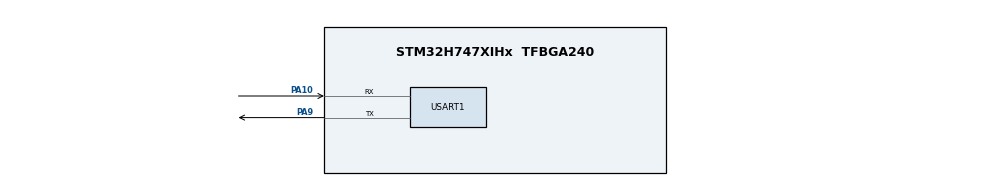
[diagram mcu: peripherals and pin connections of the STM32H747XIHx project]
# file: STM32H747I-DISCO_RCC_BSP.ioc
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Mcu.Family=STM32H7
RCC.CortexFreq_Value=400000000
RCC.HPRE=RCC_HCLK_DIV2
PH0-OSC_IN\ (PH0).PinAttribute=CortexM7
PH0-OSC_IN\ (PH0).Signal=RCC_OSC_IN
PC15-OSC32_OUT\ (OSC32_OUT).Mode=LSE-External-Oscillator
RCC.SYSCLKSource=RCC_SYSCLKSOURCE_PLLCLK
ProjectManager.StackSize=0x400
PA10.PinAttribute=CortexM7
RCC.HCLKFreq_Value=200000000
PH1-OSC_OUT\ (PH1).Mode=HSE-External-Oscillator
RCC.DIVM1=5
NVIC2.PriorityGroup=NVIC_PRIORITYGROUP_4
VP_SYS_M4_VS_Systick.Mode=SysTick
CortexM7.IPs=BDMA\:I,DMA\:I,FATFS_M7\:I,FREERTOS_M7\:I,IWDG1\:I,MDMA\:I,NVIC1\:I,RCC\:I,USB_DEVICE_M7\:I,USB_HOST_M7\:I,WWDG1\:I,CORTEX_M7\:I,DEBUG\:I,PDM2PCM_M7\:I,PWR\:I,RESMGR_UTILITY\:I,SYS\:I,OPENAMP_M7\:I,VREFBUF\:I,USART1\:I
RCC.APB3Freq_Value=100000000
Mcu.Package=TFBGA240
RCC.D1PPRE=RCC_APB3_DIV2
PA10.Signal=USART1_RX
PC14-OSC32_IN\ (OSC32_IN).Mode=LSE-External-Oscillator
RCC.APB4Freq_Value=100000000
PH0-OSC_IN\ (PH0).Mode=HSE-External-Oscillator
RCC.SupplySource=PWR_DIRECT_SMPS_SUPPLY
PH1-OSC_OUT\ (PH1).PinAttribute=CortexM7
RCC.PLLSourceVirtual=RCC_PLLSOURCE_HSE
CORTEX_M7.CPU_ICache=Enabled
PA10.Mode=Asynchronous
NVIC1.PriorityGroup=NVIC_PRIORITYGROUP_4
RCC.D2PPRE2=RCC_APB2_DIV2
RCC.D2PPRE1=RCC_APB1_DIV2
PA9.PinAttribute=CortexM7
RCC.PWR_Regulator_Voltage_Scale=PWR_REGULATOR_VOLTAGE_SCALE1
PH1-OSC_OUT\ (PH1).Signal=RCC_OSC_OUT
USART1.VirtualMode-Asynchronous=VM_ASYNC
PA9.Mode=Asynchronous
ProjectManager.TargetToolchain=STM32CubeIDE
PC15-OSC32_OUT\ (OSC32_OUT).Signal=RCC_OSC32_OUT
PC14-OSC32_IN\ (OSC32_IN).PinAttribute=CortexM7
PA9.Signal=USART1_TX
RCC.DIVN1=160
RCC.USBFreq_Value=400000000
board=STM32H747I-DISCO
RCC.APB2Freq_Value=100000000
RCC.ADCFreq_Value=50390625
Mcu.Name=STM32H747XIHx
RCC.SYSCLKFreq_VALUE=400000000
PC14-OSC32_IN\ (OSC32_IN).Signal=RCC_OSC32_IN
ProjectManager.HeapSize=0x200
PC15-OSC32_OUT\ (OSC32_OUT).PinAttribute=CortexM7
RCC.D3PPRE=RCC_APB4_DIV2
CORTEX_M7.CPU_DCache=Enabled
RCC.APB1Freq_Value=100000000
CortexM4.IPs=BDMA,DMA,FATFS_M4\:I,FREERTOS_M4\:I,IWDG2\:I,MDMA,NVIC2\:I,RCC,USB_DEVICE_M4\:I,USB_HOST_M4\:I,WWDG2\:I,ADC1\:I,DCMI\:I,TIM3\:I,DEBUG,PDM2PCM_M4\:I,PWR,RESMGR_UTILITY,SYS_M4\:I,CORTEX_M4\:I,OPENAMP_M4\:I,VREFBUF

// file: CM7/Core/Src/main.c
/* USER CODE BEGIN Header */
/**
  ******************************************************************************
  * @file           : main.c
  * @brief          : Main program body
  ******************************************************************************
  * @attention
  *
  * <h2><center>&copy; Copyright (c) 2021 STMicroelectronics.
  * All rights reserved.</center></h2>
  *
  * This software component is licensed by ST under BSD 3-Clause license,
  * the "License"; You may not use this file except in compliance with the
  * License. You may obtain a copy of the License at:
  *                        opensource.org/licenses/BSD-3-Clause
  *
  ******************************************************************************
  */
/* USER CODE END Header */
#include "main.h"

/* USER CODE BEGIN Includes */

#include "stlogo.h"

/* USER CODE END Includes */

/* USER CODE BEGIN PD */

#ifndef HSEM_ID_0
#define HSEM_ID_0 (0U) /* HW semaphore 0*/
#endif
/* USER CODE END PD */

UART_HandleTypeDef huart1;

void SystemClock_Config(void);
static void MX_GPIO_Init(void);
static void MX_USART1_UART_Init(void);
/* USER CODE BEGIN PFP */

static void Display_DemoDescription(void);
static void LCD_SetHint(void);
static void LCD_Show_Feature(uint8_t feature);

extern void SDRAM_demo (void);
extern void SDRAM_DMA_demo (void);

/* USER CODE END PFP */

int main(void)
{
/* USER CODE BEGIN Boot_Mode_Sequence_0 */
  int32_t timeout;
/* USER CODE END Boot_Mode_Sequence_0 */

  /* Enable I-Cache---------------------------------------------------------*/
  SCB_EnableICache();

  /* Enable D-Cache---------------------------------------------------------*/
  SCB_EnableDCache();

/* USER CODE BEGIN Boot_Mode_Sequence_1 */
  /* Wait until CPU2 boots and enters in stop mode or timeout*/
  timeout = 0xFFFF;
  while((__HAL_RCC_GET_FLAG(RCC_FLAG_D2CKRDY) != RESET) && (timeout-- > 0));
  if ( timeout < 0 )
  {
  Error_Handler();
  }
/* USER CODE END Boot_Mode_Sequence_1 */
  /* MCU Configuration--------------------------------------------------------*/

  /* Reset of all peripherals, Initializes the Flash interface and the Systick. */
  HAL_Init();

  /* Configure the system clock */
  SystemClock_Config();
/* USER CODE BEGIN Boot_Mode_Sequence_2 */
/* When system initialization is finished, Cortex-M7 will release Cortex-M4 by means of
HSEM notification */
/*HW semaphore Clock enable*/
__HAL_RCC_HSEM_CLK_ENABLE();
/*Take HSEM */
HAL_HSEM_FastTake(HSEM_ID_0);
/*Release HSEM in order to notify the CPU2(CM4)*/
HAL_HSEM_Release(HSEM_ID_0,0);
/* wait until CPU2 wakes up from stop mode */
timeout = 0xFFFF;
while((__HAL_RCC_GET_FLAG(RCC_FLAG_D2CKRDY) == RESET) && (timeout-- > 0));
if ( timeout < 0 )
{
Error_Handler();
}
/* USER CODE END Boot_Mode_Sequence_2 */

  /* Initialize all configured peripherals */
  MX_GPIO_Init();
  MX_USART1_UART_Init();
  /* USER CODE BEGIN 2 */

  /* Configure the Wakeup push-button in EXTI Mode */
  BSP_PB_Init(BUTTON_WAKEUP, BUTTON_MODE_EXTI);
  BSP_LED_Init(LED1);
  BSP_LED_Init(LED2);
  BSP_LED_Init(LED3);
  BSP_LED_Init(LED4);

  /*##-1- Initialize the LCD #################################################*/
  /* Initialize the LCD */
  BSP_LCD_Init(0, LCD_ORIENTATION_LANDSCAPE);
  UTIL_LCD_SetFuncDriver(&LCD_Driver);
  UTIL_LCD_SetFont(&UTIL_LCD_DEFAULT_FONT);
  Display_DemoDescription();
  HAL_Delay(2000);

  LCD_SetHint();
  HAL_Delay(2000);

  for(uint32_t feature = 0; feature < 4; feature++)
  {
	  LCD_Show_Feature(feature);
	  HAL_Delay(1000);
  }

  SDRAM_demo();
  HAL_Delay(2000);

  QSPI_demo();
  HAL_Delay(2000);

  Touchscreen_demo1();

  /* USER CODE END 2 */

  /* Infinite loop */
  /* USER CODE BEGIN WHILE */
  while (1)
  {
	  BSP_LED_Toggle(LED_GREEN);
	  BSP_LED_Toggle(LED_ORANGE);
	  BSP_LED_Toggle(LED_RED);
	  BSP_LED_Toggle(LED_BLUE);
	  HAL_Delay(200);

    /* USER CODE END WHILE */

  }
}

void SystemClock_Config(void)
{
  RCC_OscInitTypeDef RCC_OscInitStruct = {0};
  RCC_ClkInitTypeDef RCC_ClkInitStruct = {0};

  /** Supply configuration update enable
  */
  HAL_PWREx_ConfigSupply(PWR_DIRECT_SMPS_SUPPLY);
  /** Configure the main internal regulator output voltage
  */
  __HAL_PWR_VOLTAGESCALING_CONFIG(PWR_REGULATOR_VOLTAGE_SCALE1);

  while(!__HAL_PWR_GET_FLAG(PWR_FLAG_VOSRDY)) {}
  /** Initializes the RCC Oscillators according to the specified parameters
  * in the RCC_OscInitTypeDef structure.
  */
  RCC_OscInitStruct.OscillatorType = RCC_OSCILLATORTYPE_HSE;
  RCC_OscInitStruct.HSEState = RCC_HSE_ON;
  RCC_OscInitStruct.PLL.PLLState = RCC_PLL_ON;
  RCC_OscInitStruct.PLL.PLLSource = RCC_PLLSOURCE_HSE;
  RCC_OscInitStruct.PLL.PLLM = 5;
  RCC_OscInitStruct.PLL.PLLN = 160;
  RCC_OscInitStruct.PLL.PLLP = 2;
  RCC_OscInitStruct.PLL.PLLQ = 2;
  RCC_OscInitStruct.PLL.PLLR = 2;
  RCC_OscInitStruct.PLL.PLLRGE = RCC_PLL1VCIRANGE_2;
  RCC_OscInitStruct.PLL.PLLVCOSEL = RCC_PLL1VCOWIDE;
  RCC_OscInitStruct.PLL.PLLFRACN = 0;
  if (HAL_RCC_OscConfig(&RCC_OscInitStruct) != HAL_OK)
  {
    Error_Handler();
  }
  /** Initializes the CPU, AHB and APB buses clocks
  */
  RCC_ClkInitStruct.ClockType = RCC_CLOCKTYPE_HCLK|RCC_CLOCKTYPE_SYSCLK
                              |RCC_CLOCKTYPE_PCLK1|RCC_CLOCKTYPE_PCLK2
                              |RCC_CLOCKTYPE_D3PCLK1|RCC_CLOCKTYPE_D1PCLK1;
  RCC_ClkInitStruct.SYSCLKSource = RCC_SYSCLKSOURCE_PLLCLK;
  RCC_ClkInitStruct.SYSCLKDivider = RCC_SYSCLK_DIV1;
  RCC_ClkInitStruct.AHBCLKDivider = RCC_HCLK_DIV2;
  RCC_ClkInitStruct.APB3CLKDivider = RCC_APB3_DIV2;
  RCC_ClkInitStruct.APB1CLKDivider = RCC_APB1_DIV2;
  RCC_ClkInitStruct.APB2CLKDivider = RCC_APB2_DIV2;
  RCC_ClkInitStruct.APB4CLKDivider = RCC_APB4_DIV2;

  if (HAL_RCC_ClockConfig(&RCC_ClkInitStruct, FLASH_LATENCY_2) != HAL_OK)
  {
    Error_Handler();
  }
}

static void MX_USART1_UART_Init(void)
{

  huart1.Instance = USART1;
  huart1.Init.BaudRate = 115200;
  huart1.Init.WordLength = UART_WORDLENGTH_8B;
  huart1.Init.StopBits = UART_STOPBITS_1;
  huart1.Init.Parity = UART_PARITY_NONE;
  huart1.Init.Mode = UART_MODE_TX_RX;
  huart1.Init.HwFlowCtl = UART_HWCONTROL_NONE;
  huart1.Init.OverSampling = UART_OVERSAMPLING_16;
  huart1.Init.OneBitSampling = UART_ONE_BIT_SAMPLE_DISABLE;
  huart1.Init.ClockPrescaler = UART_PRESCALER_DIV1;
  huart1.AdvancedInit.AdvFeatureInit = UART_ADVFEATURE_NO_INIT;
  if (HAL_UART_Init(&huart1) != HAL_OK)
  {
    Error_Handler();
  }
  if (HAL_UARTEx_SetTxFifoThreshold(&huart1, UART_TXFIFO_THRESHOLD_1_8) != HAL_OK)
  {
    Error_Handler();
  }
  if (HAL_UARTEx_SetRxFifoThreshold(&huart1, UART_RXFIFO_THRESHOLD_1_8) != HAL_OK)
  {
    Error_Handler();
  }
  if (HAL_UARTEx_DisableFifoMode(&huart1) != HAL_OK)
  {
    Error_Handler();
  }

}

static void MX_GPIO_Init(void)
{

  /* GPIO Ports Clock Enable */
  __HAL_RCC_GPIOC_CLK_ENABLE();
  __HAL_RCC_GPIOA_CLK_ENABLE();
  __HAL_RCC_GPIOH_CLK_ENABLE();

}

/* USER CODE BEGIN 4 */

/**
  * @brief  Display main demo messages
  * @param  None
  * @retval None
  */
static void Display_DemoDescription(void)
{
  char desc[64];
  uint32_t x_size;
  uint32_t y_size;

  BSP_LCD_GetXSize(0, &x_size);
  BSP_LCD_GetYSize(0, &y_size);
  /* Set LCD Foreground Layer  */
  UTIL_LCD_SetFont(&UTIL_LCD_DEFAULT_FONT);

  /* Clear the LCD */
  UTIL_LCD_SetBackColor(UTIL_LCD_COLOR_WHITE);
  UTIL_LCD_Clear(UTIL_LCD_COLOR_WHITE);

  /* Set the LCD Text Color */
  UTIL_LCD_SetTextColor(UTIL_LCD_COLOR_DARKBLUE);

  /* Display LCD messages */
  UTIL_LCD_DisplayStringAt(0, 10, (uint8_t *)"STM32H747I BSP", CENTER_MODE);
  UTIL_LCD_DisplayStringAt(0, 35, (uint8_t *)"Drivers examples", CENTER_MODE);

  /* Draw Bitmap */
//  UTIL_LCD_DrawBitmap((x_size - 80)/2, 65, (uint8_t *)stlogo);

  UTIL_LCD_SetFont(&Font12);
  UTIL_LCD_DisplayStringAt(0, y_size - 20, (uint8_t *)"Copyright (c) STMicroelectronics 2018", CENTER_MODE);

  UTIL_LCD_SetFont(&Font16);
  BSP_LCD_FillRect(0, 0, y_size/2 + 15, x_size, 60, UTIL_LCD_COLOR_BLUE);
  UTIL_LCD_SetTextColor(UTIL_LCD_COLOR_WHITE);
  UTIL_LCD_SetBackColor(UTIL_LCD_COLOR_BLUE);
  UTIL_LCD_DisplayStringAt(0, y_size / 2 + 30, (uint8_t *)"Press Wakeup button to start :", CENTER_MODE);
//  sprintf(desc,"%s example", BSP_examples[DemoIndex].DemoName);
  UTIL_LCD_DisplayStringAt(0, y_size/2 + 45, (uint8_t *)desc, CENTER_MODE);
}

/**
  * @brief  Display LCD demo hint
  * @param  None
  * @retval None
  */
static void LCD_SetHint(void)
{
  uint32_t x_size;
  uint32_t y_size;
  BSP_LCD_GetXSize(0, &x_size);
  BSP_LCD_GetYSize(0, &y_size);
  /* Clear the LCD */
  UTIL_LCD_Clear(UTIL_LCD_COLOR_WHITE);

  /*  Set the LCD Text Color */
  UTIL_LCD_SetTextColor(UTIL_LCD_COLOR_DARKBLUE);
  UTIL_LCD_FillRect(0, 0, x_size, 80, UTIL_LCD_COLOR_BLUE);
  UTIL_LCD_SetTextColor(UTIL_LCD_COLOR_WHITE);
  UTIL_LCD_SetBackColor(UTIL_LCD_COLOR_BLUE);
  UTIL_LCD_SetFont(&Font24);
  UTIL_LCD_DisplayStringAt(0, 0, (uint8_t *)"LCD", CENTER_MODE);
  UTIL_LCD_SetFont(&Font12);
  UTIL_LCD_DisplayStringAt(0, 30, (uint8_t *)"This example shows the different", CENTER_MODE);
  UTIL_LCD_DisplayStringAt(0, 45, (uint8_t *)"LCD Features, use Tamper push-button to display", CENTER_MODE);
  UTIL_LCD_DisplayStringAt(0, 60, (uint8_t *)"next page", CENTER_MODE);

  UTIL_LCD_DrawRect(10, 90, x_size - 20, y_size- 100, UTIL_LCD_COLOR_BLUE);
  UTIL_LCD_DrawRect(11, 91, x_size - 22, y_size- 102, UTIL_LCD_COLOR_BLUE);
 }

/**
  * @brief  Show LCD Features
  * @param  feature : feature index
  * @retval None
  */
static void LCD_Show_Feature(uint8_t feature)
{
  Point Points[]= {{220, 220}, {280, 180}, {320, 180}, {370, 220}, {370, 260}, {320, 310}, {280, 310}, {220, 260}};
  Point Points2[3];
  uint32_t x_size, y_size;
  int32_t i = 0;
  uint8_t text[50];
  BSP_LCD_GetXSize(0, &x_size);
  BSP_LCD_GetYSize(0, &y_size);

  Points2[0].X = x_size - 80;
  Points2[0].Y = 150;
  Points2[1].X = x_size - 20;
  Points2[1].Y = 150;
  Points2[2].X = x_size - 20;
  Points2[2].Y = 200;

  UTIL_LCD_SetBackColor(UTIL_LCD_COLOR_WHITE);
  UTIL_LCD_SetTextColor(UTIL_LCD_COLOR_WHITE);
  UTIL_LCD_FillRect(12, 92, x_size - 24, y_size- 104, UTIL_LCD_COLOR_WHITE);
  UTIL_LCD_SetTextColor(UTIL_LCD_COLOR_BLACK);

  switch (feature)
  {
  case 0:
    /* Text Feature */

    UTIL_LCD_DisplayStringAt(14, 100, (uint8_t *)"Left aligned Text", LEFT_MODE);
    UTIL_LCD_DisplayStringAt(0, 115, (uint8_t *)"Center aligned Text", CENTER_MODE);
    UTIL_LCD_DisplayStringAt(14, 130, (uint8_t*)"Right aligned Text", RIGHT_MODE);
    UTIL_LCD_SetFont(&Font24);
    UTIL_LCD_DisplayStringAt(14, 180, (uint8_t *)"Font24", LEFT_MODE);
    UTIL_LCD_SetFont(&Font20);
    UTIL_LCD_DisplayStringAt(x_size/2 -20, 180, (uint8_t *)"Font20", LEFT_MODE);
    UTIL_LCD_SetFont(&Font16);
    UTIL_LCD_DisplayStringAt(x_size - 80, 184, (uint8_t *)"Font16", LEFT_MODE);
    break;

  case 1:

    /* Draw misc. Shapes */
    UTIL_LCD_SetTextColor(UTIL_LCD_COLOR_BLACK);
    UTIL_LCD_DrawRect(20, 100, 60 , 40, UTIL_LCD_COLOR_BLACK);
    UTIL_LCD_FillRect(100, 100, 60 , 40, UTIL_LCD_COLOR_BLACK);

    UTIL_LCD_DrawCircle(x_size - 120, 120, 20, UTIL_LCD_COLOR_GRAY);
    UTIL_LCD_FillCircle(x_size - 40, 120, 20, UTIL_LCD_COLOR_GRAY);

    UTIL_LCD_FillPolygon(Points, 8, UTIL_LCD_COLOR_GREEN);

    UTIL_LCD_DrawEllipse(130, 170, 30, 20, UTIL_LCD_COLOR_RED);
    UTIL_LCD_FillEllipse(200, 170, 30, 20, UTIL_LCD_COLOR_RED);

    UTIL_LCD_DrawHLine(20, y_size - 30, x_size / 5, UTIL_LCD_COLOR_BLACK);
    UTIL_LCD_DrawLine (100, y_size - 20, 230, y_size- 50, UTIL_LCD_COLOR_BLACK);
    UTIL_LCD_DrawLine (100, y_size- 50, 230, y_size- 20, UTIL_LCD_COLOR_BLACK);

    UTIL_LCD_DrawPolygon(Points2, 3, UTIL_LCD_COLOR_GREEN);
    HAL_Delay(2000);
    break;

  case 2:
    /* Draw Bitmap */
    /* Draw Bitmap */
    UTIL_LCD_DrawBitmap(20, 100, (uint8_t *)stlogo);
    HAL_Delay(500);

    UTIL_LCD_DrawBitmap(x_size/2 - 40, 100, (uint8_t *)stlogo);
    HAL_Delay(500);

    UTIL_LCD_DrawBitmap(x_size-100, 100, (uint8_t *)stlogo);
    HAL_Delay(500);

    UTIL_LCD_DrawBitmap(20, y_size- 80, (uint8_t *)stlogo);
    HAL_Delay(500);

    UTIL_LCD_DrawBitmap(x_size/2 - 40, y_size- 80, (uint8_t *)stlogo);
    HAL_Delay(500);

    UTIL_LCD_DrawBitmap(x_size-100, y_size- 80, (uint8_t *)stlogo);
    HAL_Delay(500);
    break;

  case 3:
    UTIL_LCD_SetFont(&Font24);
    /* Set the LCD Back Color and Text Color*/
    UTIL_LCD_SetBackColor(UTIL_LCD_COLOR_WHITE);
    UTIL_LCD_SetTextColor(UTIL_LCD_COLOR_GREEN);

    /*  Set the brightness */
    for( i = 100; i >= 0; i-=10)
    {
      sprintf((char*)text," Brightness  =  %d ",(int)i);
      UTIL_LCD_DisplayStringAt(0, x_size/2 + 45, (uint8_t *)text, CENTER_MODE);
      BSP_LCD_SetBrightness(0,i);
      HAL_Delay(300);
    }

    for( i = 0; i <= 100; i+=10)
    {
      sprintf((char*)text," Brightness  =  %d ",(int)i);
      UTIL_LCD_DisplayStringAt(0, x_size/2 + 45, (uint8_t *)text, CENTER_MODE);
      BSP_LCD_SetBrightness(0,i);
      HAL_Delay(300);
    }
    break;
  }
}

/* USER CODE END 4 */

void Error_Handler(void)
{
  __disable_irq();
  while (1)
  {
  }
}

/************************ (C) COPYRIGHT STMicroelectronics *****END OF FILE****/
